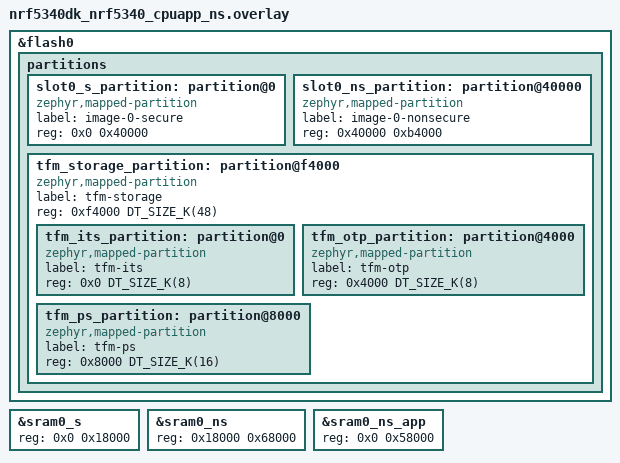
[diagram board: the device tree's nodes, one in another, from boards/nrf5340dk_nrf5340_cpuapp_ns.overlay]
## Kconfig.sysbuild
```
#
# Copyright (c) 2023 Nordic Semiconductor
#
# SPDX-License-Identifier: LicenseRef-Nordic-5-Clause
#

config PARTITION_MANAGER
	default n

source "${ZEPHYR_BASE}/share/sysbuild/Kconfig"

config NRF_DEFAULT_IPC_RADIO
	default y
```

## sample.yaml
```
sample:
  description: Wi-Fi Fundamentals Course by Nordic Developer Academy (https://academy.nordicsemi.com/)
  name: Wi-Fi Fundamentals Course - Lesson 2 Exercise 3 
  
common: 
    sysbuild: true
    build_only: true
    skip: true
    
tests:
  wifi_fund.l2.e3.nrf5340dk: 
    extra_args: SHIELD=nrf7002ek
    integration_platforms: 
      - nrf5340dk/nrf5340/cpuapp/ns
    platform_allow:
      - nrf5340dk/nrf5340/cpuapp/ns

  
  wifi_fund.l2.e3.nrf7002dk:
    integration_platforms: 
      - nrf7002dk/nrf5340/cpuapp/ns
    platform_allow:
      - nrf7002dk/nrf5340/cpuapp/ns
```

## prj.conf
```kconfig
#
# Copyright (c) 2022 Nordic Semiconductor ASA
#
# SPDX-License-Identifier: LicenseRef-Nordic-5-Clause
#

# Wi-Fi
CONFIG_WIFI=y
CONFIG_NRF70_SR_COEX=y
CONFIG_NRF70_SR_COEX_RF_SWITCH=y

# WPA supplicant
CONFIG_WIFI_NM_WPA_SUPPLICANT=y
CONFIG_WIFI_NM_WPA_SUPPLICANT_LOG_LEVEL_OFF=y

CONFIG_WIFI_CREDENTIALS=y
CONFIG_WIFI_CREDENTIALS_MAX_ENTRIES=1

# Logging
CONFIG_LOG=y

# DK library
CONFIG_DK_LIBRARY=y

# System settings
CONFIG_NEWLIB_LIBC=y
CONFIG_NEWLIB_LIBC_NANO=n

# Networking Management API
CONFIG_NET_MGMT=y
CONFIG_NET_MGMT_EVENT=y
CONFIG_NET_MGMT_EVENT_INFO=y
CONFIG_NET_MGMT_EVENT_STACK_SIZE=22000
CONFIG_NET_MGMT_EVENT_QUEUE_TIMEOUT=5000
CONFIG_NET_CONNECTION_MANAGER=y
CONFIG_L2_WIFI_CONNECTIVITY=y

# Networking
CONFIG_NETWORKING=y
CONFIG_NET_IPV4=y
CONFIG_NET_IPV6=n
CONFIG_NET_NATIVE=y
CONFIG_NET_SOCKETS=y
CONFIG_NET_L2_ETHERNET=y
CONFIG_NET_L2_WIFI_MGMT=y
CONFIG_NET_DHCPV4=y

# Memory
CONFIG_SYSTEM_WORKQUEUE_STACK_SIZE=4096
CONFIG_MAIN_STACK_SIZE=5200

CONFIG_NANOPB=y



# Bluetooth LE
# STEP 1.1 - Enable the necessary Bluetooth LE configurations


# Storing credentials
# STEP 1.2 - Enable the necessary NVS and flash configurations


# BT enables MbedTLS heap but uses the default heap size which is not enough for Wi-Fi.
CONFIG_MBEDTLS_HEAP_SIZE=8192

CONFIG_NET_PKT_BUF_TX_DATA_POOL_SIZE=5000
CONFIG_NET_PKT_BUF_RX_DATA_POOL_SIZE=5000
```

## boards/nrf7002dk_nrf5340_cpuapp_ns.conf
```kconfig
# UART1 is used for TF-M logging should be disabled
CONFIG_TFM_SECURE_UART=n
CONFIG_TFM_LOG_LEVEL_SILENCE=y

CONFIG_WIFI_CREDENTIALS_BACKEND_SETTINGS=n
CONFIG_WIFI_CREDENTIALS_BACKEND_PSA=y
CONFIG_TFM_PROFILE_TYPE_MEDIUM=y
 
```

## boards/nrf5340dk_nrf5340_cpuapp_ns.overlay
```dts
/ {
    /delete-node/ nrf-gpio-forwarder;
};

/*
 * Copyright (c) 2026 Nordic Semiconductor ASA
 *
 * SPDX-License-Identifier: LicenseRef-Nordic-5-Clause
 */

/delete-node/ &boot_partition;
/delete-node/ &slot0_partition;
/delete-node/ &slot1_partition;
/delete-node/ &tfm_its_partition;
/delete-node/ &tfm_otp_partition;
/delete-node/ &tfm_ps_partition;

&flash0 {
	partitions {
		slot0_s_partition: partition@0 {
			compatible = "zephyr,mapped-partition";
			label = "image-0-secure";
			reg = <0x0 0x40000>;
		};

		slot0_ns_partition: partition@40000 {
			compatible = "zephyr,mapped-partition";
			label = "image-0-nonsecure";
			reg = <0x40000 0xb4000>;
		};

		tfm_storage_partition: partition@f4000 {
			compatible = "zephyr,mapped-partition";
			label = "tfm-storage";
			reg = <0xf4000 DT_SIZE_K(48)>;
			ranges = <0x0 0xf4000 DT_SIZE_K(48)>;
			#address-cells = <1>;
			#size-cells = <1>;

			tfm_its_partition: partition@0 {
				compatible = "zephyr,mapped-partition";
				label = "tfm-its";
				reg = <0x0 DT_SIZE_K(8)>;
			};

			tfm_otp_partition: partition@4000 {
				compatible = "zephyr,mapped-partition";
				label = "tfm-otp";
				reg = <0x4000 DT_SIZE_K(8)>;
			};

			tfm_ps_partition: partition@8000 {
				compatible = "zephyr,mapped-partition";
				label = "tfm-ps";
				reg = <0x8000 DT_SIZE_K(16)>;
			};
		};
	};
};

&sram0_s {
	reg = <0x0 0x18000>;
};

&sram0_ns {
	reg = <0x18000 0x68000>;
	ranges = <0x0 0x18000 0x68000>;
};

&sram0_ns_app {
	reg = <0x0 0x58000>;
};
```

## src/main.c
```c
/*
 * Copyright (c) 2023 Nordic Semiconductor ASA
 *
 * SPDX-License-Identifier: LicenseRef-Nordic-5-Clause
 */

#include <errno.h>
#include <stddef.h>
#include <string.h>
#include <stdio.h>
#include <zephyr/kernel.h>
#include <zephyr/types.h>
#include <zephyr/logging/log.h>

#include <dk_buttons_and_leds.h>

#include <zephyr/net/wifi.h>
#include <zephyr/net/wifi_mgmt.h>
#include <zephyr/net/net_mgmt.h>
#include <net/wifi_mgmt_ext.h>
#include <zephyr/net/wifi_credentials.h>

/* STEP 2 - Include the header files for Bluetooth LE */


LOG_MODULE_REGISTER(Lesson2_Exercise3, LOG_LEVEL_INF);

#define EVENT_MASK (NET_EVENT_L4_CONNECTED | NET_EVENT_L4_DISCONNECTED)

static struct net_mgmt_event_callback mgmt_cb;
static bool wifi_connected;

static void net_mgmt_event_handler(struct net_mgmt_event_callback *cb, uint64_t mgmt_event,
				   struct net_if *iface)
{
	if ((mgmt_event & EVENT_MASK) != mgmt_event) {
		return;
	}
	if (mgmt_event == NET_EVENT_L4_CONNECTED) {
		LOG_INF("Network connected");
		wifi_connected = true;
		dk_set_led_on(DK_LED1);
		return;
	}
	if (mgmt_event == NET_EVENT_L4_DISCONNECTED) {
		if (wifi_connected == false) {
			LOG_INF("Waiting for network to be connected");
		} else {
			dk_set_led_off(DK_LED1);
			LOG_INF("Network disconnected");
			wifi_connected = false;
		}
		return;
	}
}

#define ADV_DATA_UPDATE_INTERVAL      5

#define ADV_PARAM_UPDATE_DELAY        1

/* STEP 3.2 - Define indexes for accessing prov_svc_data */


#define PROV_BT_LE_ADV_PARAM_FAST BT_LE_ADV_PARAM(BT_LE_ADV_OPT_CONNECTABLE, \
						BT_GAP_ADV_FAST_INT_MIN_2, \
						BT_GAP_ADV_FAST_INT_MAX_2, NULL)

#define PROV_BT_LE_ADV_PARAM_SLOW BT_LE_ADV_PARAM(BT_LE_ADV_OPT_CONNECTABLE, \
						BT_GAP_ADV_SLOW_INT_MIN, \
						BT_GAP_ADV_SLOW_INT_MAX, NULL)

#define ADV_DAEMON_STACK_SIZE 4096
#define ADV_DAEMON_PRIORITY   5

K_THREAD_STACK_DEFINE(adv_daemon_stack_area, ADV_DAEMON_STACK_SIZE);
static struct k_work_q adv_daemon_work_q;

/* STEP 3.1 Define an array for storing provisioning service data */


/* STEP 4.1 Define a variable for the device name */



/* STEP 4.2 - Define the data structure for the advertisement packet */


/* STEP 4.3 - Define the data structure for the scan response packet */


/* STEP 6 - Define the work structures for updating advertisement parameters and data */


static void update_wifi_status_in_adv(void)
{

	/* STEP 5.1 - Update the firmware version*/


	/* STEP 5.2 - Update the provisioning state */


	/* STEP 5.3 - Update the Wi-Fi connection status*/

}

static void connected(struct bt_conn *conn, uint8_t err)
{
	char addr[BT_ADDR_LE_STR_LEN];

	if (err) {
		LOG_ERR("BT Connection failed (err 0x%02x).\n", err);
		return;
	}

	bt_addr_le_to_str(bt_conn_get_dst(conn), addr, sizeof(addr));
	LOG_INF("BT Connected: %s", addr);

	/* STEP 8.1 - Upon a connected event, cancel update_adv_data_work */

}

static void disconnected(struct bt_conn *conn, uint8_t reason)
{
	char addr[BT_ADDR_LE_STR_LEN];

	bt_addr_le_to_str(bt_conn_get_dst(conn), addr, sizeof(addr));
	LOG_INF("BT Disconnected: %s (reason 0x%02x).\n", addr, reason);

	/* STEP 8.2 - Upon a disconnected event, reschedule all work items*/

}

static void identity_resolved(struct bt_conn *conn, const bt_addr_le_t *rpa,
				const bt_addr_le_t *identity)
{
	char addr_identity[BT_ADDR_LE_STR_LEN];
	char addr_rpa[BT_ADDR_LE_STR_LEN];

	bt_addr_le_to_str(identity, addr_identity, sizeof(addr_identity));
	bt_addr_le_to_str(rpa, addr_rpa, sizeof(addr_rpa));

	LOG_INF("BT Identity resolved %s -> %s.\n", addr_rpa, addr_identity);
}

static void security_changed(struct bt_conn *conn, bt_security_t level,
				enum bt_security_err err)
{
	char addr[BT_ADDR_LE_STR_LEN];

	bt_addr_le_to_str(bt_conn_get_dst(conn), addr, sizeof(addr));

	if (!err) {
		LOG_INF("BT Security changed: %s level %u.\n", addr, level);
	} else {
		LOG_ERR("BT Security failed: %s level %u err %d.\n", addr, level, err);
	}
}

BT_CONN_CB_DEFINE(conn_callbacks) = {
	.connected = connected,
	.disconnected = disconnected,
	.identity_resolved = identity_resolved,
	.security_changed = security_changed,
};

static void auth_cancel(struct bt_conn *conn)
{
	char addr[BT_ADDR_LE_STR_LEN];

	bt_addr_le_to_str(bt_conn_get_dst(conn), addr, sizeof(addr));

	LOG_INF("BT Pairing cancelled: %s.\n", addr);
}

static struct bt_conn_auth_cb auth_cb_display = {
	.cancel = auth_cancel,
};

static void pairing_complete(struct bt_conn *conn, bool bonded)
{
	char addr[BT_ADDR_LE_STR_LEN];

	bt_addr_le_to_str(bt_conn_get_dst(conn), addr, sizeof(addr));
	LOG_INF("BT pairing completed: %s, bonded: %d\n", addr, bonded);
}

static void pairing_failed(struct bt_conn *conn, enum bt_security_err reason)
{
	LOG_INF("BT Pairing Failed (%d). Disconnecting.\n", reason);
	bt_conn_disconnect(conn, BT_HCI_ERR_AUTH_FAIL);
}

static struct bt_conn_auth_info_cb auth_info_cb_display = {

	.pairing_complete = pairing_complete,
	.pairing_failed = pairing_failed,
};

static void update_adv_data_task(struct k_work *item)
{
	/* STEP 7.2 - Update the advertising and scan response data*/

}

static void update_adv_param_task(struct k_work *item)
{
	/* STEP 7.1 - Stop advertising, then start advertising again */

}

static void byte_to_hex(char *ptr, uint8_t byte, char base)
{
	int i, val;

	for (i = 0, val = (byte & 0xf0) >> 4; i < 2; i++, val = byte & 0x0f) {
		if (val < 10) {
			*ptr++ = (char) (val + '0');
		} else {
			*ptr++ = (char) (val - 10 + base);
		}
	}
}

static void update_dev_name(struct net_linkaddr *mac_addr)
{
	byte_to_hex(&device_name[2], mac_addr->addr[3], 'A');
	byte_to_hex(&device_name[4], mac_addr->addr[4], 'A');
	byte_to_hex(&device_name[6], mac_addr->addr[5], 'A');
}

int main(void)
{
	int err;
	
	if (dk_leds_init() != 0) {
		LOG_ERR("Failed to initialize the LED library");
	}

	/* Sleep 1 seconds to allow initialization of wifi driver. */
	k_sleep(K_SECONDS(1));

	net_mgmt_init_event_callback(&mgmt_cb, net_mgmt_event_handler, EVENT_MASK);
	net_mgmt_add_event_callback(&mgmt_cb);

	bt_conn_auth_cb_register(&auth_cb_display);
	bt_conn_auth_info_cb_register(&auth_info_cb_display);

	err = bt_enable(NULL);
	if (err) {
		LOG_ERR("Bluetooth init failed (err %d).\n", err);
		return 0;
	}
	LOG_INF("Bluetooth initialized.\n");

	/* STEP 9 - Enable the Bluetooth Wi-Fi Provisioning Service */


	/* STEP 10.1 Prepare the advertisement data */

	/* STEP 10.2 - Start advertising */


	k_work_queue_init(&adv_daemon_work_q);
	k_work_queue_start(&adv_daemon_work_q, adv_daemon_stack_area,
			K_THREAD_STACK_SIZEOF(adv_daemon_stack_area), ADV_DAEMON_PRIORITY,
			NULL);

	/* STEP 11 - Initializa all work items to their respective task */


	/* STEP 12 - Apply stored Wi-Fi credentials */


	return 0;
}
```
